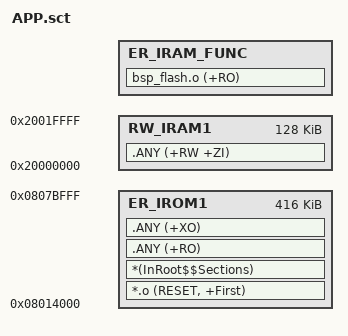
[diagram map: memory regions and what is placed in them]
; *************************************************************
; *** Scatter-Loading Description File generated by uVision ***
; *************************************************************

LR_IROM1 0x08014000 0x00068000 {
  ER_IROM1 0x08014000 0x00068000 {
   *.o (RESET, +First)
   *(InRoot$$Sections)
   .ANY (+RO)
   .ANY (+XO)
  }
  RW_IRAM1 0x20000000 0x00020000 { .ANY (+RW +ZI) }
  ER_IRAM_FUNC +0 {
   bsp_flash.o (+RO)
  }
}

